# STM32F423 register map
File version: 1.2
CPU: CM4 r0p1, little endian, MPU, FPU, 4 interrupt priority bits
Registers are 32-bit, read-write, reset 0x0 unless marked. A register's access mark holds for its fields unless they carry their own. Offsets are from the block's base; [hi:lo] are bit positions; {n}, {i} and the like mark numbered series.

## RCC — Reset and clock control
Base 0x40023800
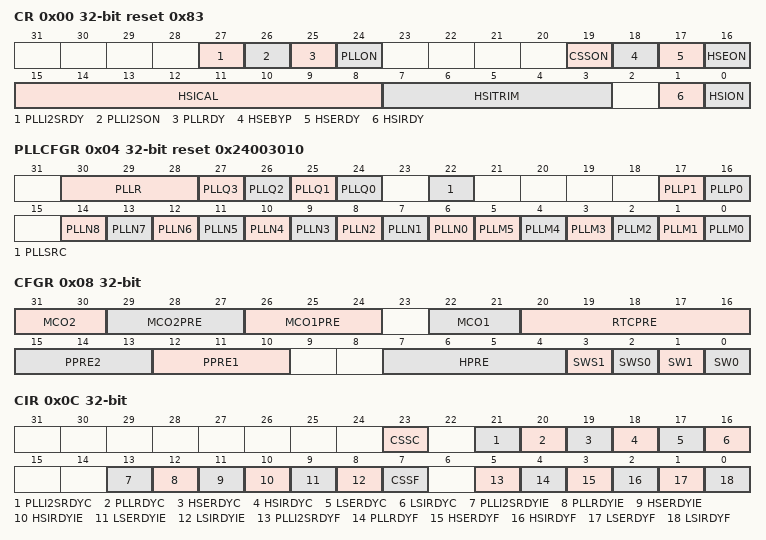
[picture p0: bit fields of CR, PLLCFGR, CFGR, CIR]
0x00 CR reset 0x83 — clock control register
  [27] PLLI2SRDY — PLLI2S clock ready flag
  [26] PLLI2SON — PLLI2S enable
  [25] PLLRDY — Main PLL (PLL) clock ready flag
  [24] PLLON — Main PLL (PLL) enable
  [19] CSSON — Clock security system enable
  [18] HSEBYP — HSE clock bypass
  [17] HSERDY — HSE clock ready flag
  [16] HSEON — HSE clock enable
  [15:8] HSICAL — Internal high-speed clock calibration
  [7:3] HSITRIM — Internal high-speed clock trimming
  [1] HSIRDY — Internal high-speed clock ready flag
  [0] HSION — Internal high-speed clock enable
0x04 PLLCFGR reset 0x24003010 — PLL configuration register
  [30:28] PLLR — Main PLL (PLL) division factor for I2S, DFSDM clocks
  [n+24] PLLQ{n} (n=0..3) — Main PLL (PLL) division factor for USB OTG FS, SDIO and random number generator clocks
  [22] PLLSRC — Main PLL(PLL) and audio PLL (PLLI2S) entry clock source
  [17] PLLP1 — Main PLL (PLL) division factor for main system clock
  [16] PLLP0 — Main PLL (PLL) division factor for main system clock
  [n+6] PLLN{n} (n=0..8) — Main PLL (PLL) multiplication factor for VCO
  [n] PLLM{n} (n=0..5) — Division factor for the main PLL (PLL) and audio PLL (PLLI2S) input clock
0x08 CFGR access per field — clock configuration register
  [31:30] MCO2 rw — Microcontroller clock output 2
  [29:27] MCO2PRE rw — MCO2 prescaler
  [26:24] MCO1PRE rw — MCO1 prescaler
  [22:21] MCO1 rw — Microcontroller clock output 1
  [20:16] RTCPRE rw — HSE division factor for RTC clock
  [15:13] PPRE2 rw — APB high-speed prescaler (APB2)
  [12:10] PPRE1 rw — APB Low speed prescaler (APB1)
  [7:4] HPRE rw — AHB prescaler
  [3] SWS1 ro — System clock switch status
  [2] SWS0 ro — System clock switch status
  [1] SW1 rw — System clock switch
  [0] SW0 rw — System clock switch
0x0C CIR access per field — clock interrupt register
  [23] CSSC wo — Clock security system interrupt clear
  [21] PLLI2SRDYC wo — PLLI2S ready interrupt clear
  [20] PLLRDYC wo — Main PLL(PLL) ready interrupt clear
  [19] HSERDYC wo — HSE ready interrupt clear
  [18] HSIRDYC wo — HSI ready interrupt clear
  [17] LSERDYC wo — LSE ready interrupt clear
  [16] LSIRDYC wo — LSI ready interrupt clear
  [13] PLLI2SRDYIE rw — PLLI2S ready interrupt enable
  [12] PLLRDYIE rw — Main PLL (PLL) ready interrupt enable
  [11] HSERDYIE rw — HSE ready interrupt enable
  [10] HSIRDYIE rw — HSI ready interrupt enable
  [9] LSERDYIE rw — LSE ready interrupt enable
  [8] LSIRDYIE rw — LSI ready interrupt enable
  [7] CSSF ro — Clock security system interrupt flag
  [5] PLLI2SRDYF ro — PLLI2S ready interrupt flag
  [4] PLLRDYF ro — Main PLL (PLL) ready interrupt flag
  [3] HSERDYF ro — HSE ready interrupt flag
  [2] HSIRDYF ro — HSI ready interrupt flag
  [1] LSERDYF ro — LSE ready interrupt flag
  [0] LSIRDYF ro — LSI ready interrupt flag
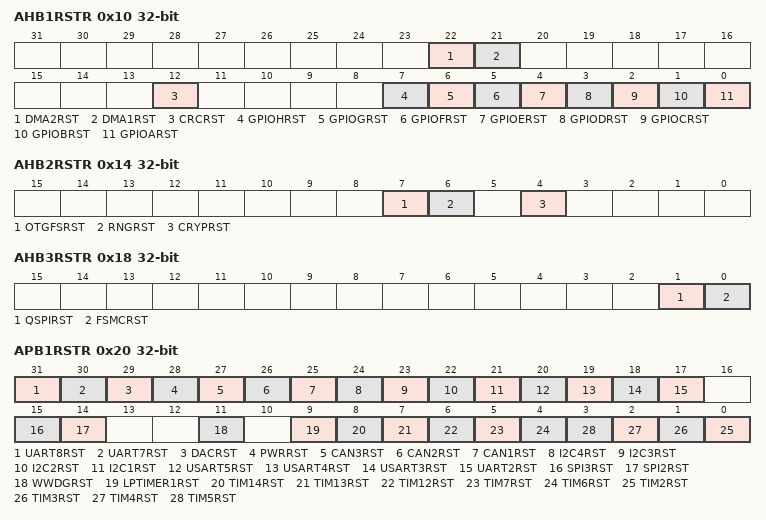
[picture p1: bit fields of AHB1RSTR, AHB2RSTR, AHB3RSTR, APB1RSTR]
0x10 AHB1RSTR — AHB1 peripheral reset register
  [22] DMA2RST — DMA2 reset
  [21] DMA1RST — DMA2 reset
  [12] CRCRST — CRC reset
  [7] GPIOHRST — IO port H reset
  [6] GPIOGRST — IO port G reset
  [5] GPIOFRST — IO port F reset
  [4] GPIOERST — IO port E reset
  [3] GPIODRST — IO port D reset
  [2] GPIOCRST — IO port C reset
  [1] GPIOBRST — IO port B reset
  [0] GPIOARST — IO port A reset
0x14 AHB2RSTR — AHB2 peripheral reset register
  [7] OTGFSRST — USB OTG FS module reset
  [6] RNGRST
  [4] CRYPRST — CRYP module reset
0x18 AHB3RSTR — peripheral reset register
  [1] QSPIRST — QUADSPI module reset
  [0] FSMCRST — Flexible memory controller module reset
0x20 APB1RSTR — APB1 peripheral reset register
  [31] UART8RST — UART 8 reset
  [30] UART7RST — UART 7 reset
  [29] DACRST — DAC reset
  [28] PWRRST — Power interface reset
  [27] CAN3RST — CAN 3 reset
  [26] CAN2RST
  [25] CAN1RST
  [24] I2C4RST
  [23] I2C3RST — I2C3 reset
  [22] I2C2RST — I2C 2 reset
  [21] I2C1RST — I2C 1 reset
  [20] USART5RST — USART5 reset
  [19] USART4RST — USART4 reset
  [18] USART3RST
  [17] UART2RST — USART 2 reset
  [15] SPI3RST — SPI 3 reset
  [14] SPI2RST — SPI 2 reset
  [11] WWDGRST — Window watchdog reset
  [9] LPTIMER1RST — LPTimer1 reset
  [8] TIM14RST
  [7] TIM13RST
  [6] TIM12RST
  [5] TIM7RST
  [4] TIM6RST
  [n-2] TIM{n}RST (n=2..5) — TIM{n} reset
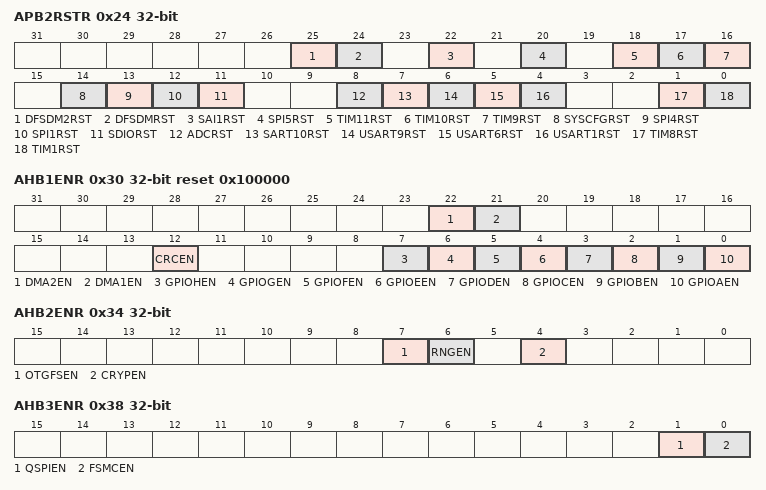
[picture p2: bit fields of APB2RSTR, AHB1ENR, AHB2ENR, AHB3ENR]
0x24 APB2RSTR — APB2 peripheral reset register
  [25] DFSDM2RST — DFSDM2 reset
  [24] DFSDMRST
  [22] SAI1RST — SAI1 reset
  [20] SPI5RST
  [18] TIM11RST — TIM11 reset
  [17] TIM10RST — TIM10 reset
  [16] TIM9RST — TIM9 reset
  [14] SYSCFGRST — System configuration controller reset
  [13] SPI4RST — SPI4 reset
  [12] SPI1RST — SPI 1 reset
  [11] SDIORST — SDIO reset
  [8] ADCRST — ADC interface reset (common to all ADCs)
  [7] SART10RST — USART10 reset
  [6] USART9RST — USART9 reset
  [5] USART6RST — USART6 reset
  [4] USART1RST — USART1 reset
  [1] TIM8RST
  [0] TIM1RST — TIM1 reset
0x30 AHB1ENR reset 0x100000 — AHB1 peripheral clock register
  [22] DMA2EN — DMA2 clock enable
  [21] DMA1EN — DMA1 clock enable
  [12] CRCEN — CRC clock enable
  [7] GPIOHEN — IO port H clock enable
  [6] GPIOGEN — IO port G clock enable
  [5] GPIOFEN — IO port F clock enable
  [4] GPIOEEN — IO port E clock enable
  [3] GPIODEN — IO port D clock enable
  [2] GPIOCEN — IO port C clock enable
  [1] GPIOBEN — IO port B clock enable
  [0] GPIOAEN — IO port A clock enable
0x34 AHB2ENR — AHB2 peripheral clock enable register
  [7] OTGFSEN — USB OTG FS clock enable
  [6] RNGEN
  [4] CRYPEN — CRYP clock enable
0x38 AHB3ENR — AHB3 peripheral clock enable register
  [1] QSPIEN — QUADSPI memory controller module clock enable
  [0] FSMCEN — Flexible memory controller module clock enable
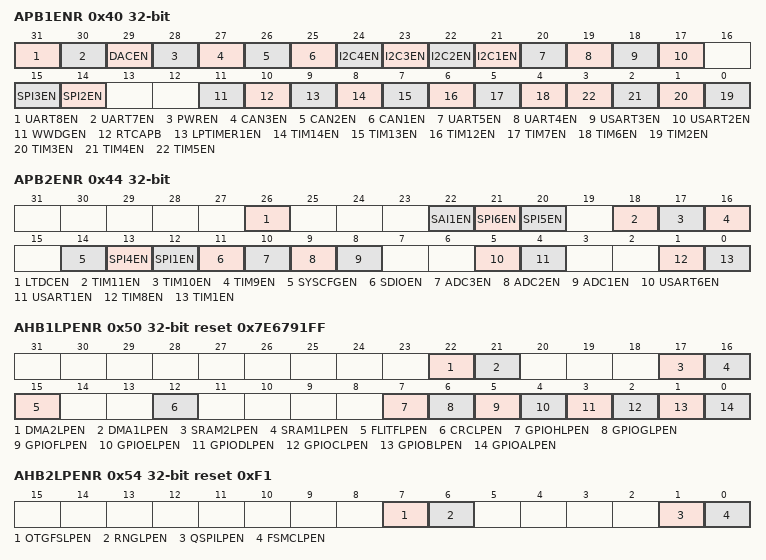
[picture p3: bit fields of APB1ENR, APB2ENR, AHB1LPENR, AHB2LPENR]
0x40 APB1ENR — APB1 peripheral clock enable register
  [31] UART8EN — UART8 clock enable
  [30] UART7EN — UART7 clock enable
  [29] DACEN — DAC clock enable
  [28] PWREN — Power interface clock enable
  [27] CAN3EN — CAN 3 clock enable
  [26] CAN2EN
  [25] CAN1EN
  [24] I2C4EN
  [23] I2C3EN — I2C3 clock enable
  [22] I2C2EN — I2C2 clock enable
  [21] I2C1EN — I2C1 clock enable
  [20] UART5EN — UART 5 clock enable
  [19] UART4EN — UART 4 clock enable
  [18] USART3EN
  [17] USART2EN — USART 2 clock enable
  [15] SPI3EN — SPI3 clock enable
  [14] SPI2EN — SPI2 clock enable
  [11] WWDGEN — Window watchdog clock enable
  [10] RTCAPB — clock enable
  [9] LPTIMER1EN — LPTimer 1 clock enable
  [8] TIM14EN
  [7] TIM13EN
  [6] TIM12EN
  [5] TIM7EN
  [4] TIM6EN
  [n-2] TIM{n}EN (n=2..5) — TIM{n} clock enable
0x44 APB2ENR — APB2 peripheral clock enable register
  [26] LTDCEN — LTDC clock enable
  [22] SAI1EN — SAI 1 clock enable
  [21] SPI6EN — SPI6 clock enable
  [20] SPI5EN — SPI5 clock enable
  [18] TIM11EN — TIM11 clock enable
  [17] TIM10EN — TIM10 clock enable
  [16] TIM9EN — TIM9 clock enable
  [14] SYSCFGEN — System configuration controller clock enable
  [13] SPI4EN — SPI4 clock enable
  [12] SPI1EN — SPI1 clock enable
  [11] SDIOEN — SDIO clock enable
  [10] ADC3EN — ADC3 clock enable
  [9] ADC2EN — ADC2 clock enable
  [8] ADC1EN — ADC1 clock enable
  [5] USART6EN — USART6 clock enable
  [4] USART1EN — USART1 clock enable
  [1] TIM8EN
  [0] TIM1EN — TIM1 clock enable
0x50 AHB1LPENR reset 0x7E6791FF — AHB1 peripheral clock enable in low power mode register
  [22] DMA2LPEN — DMA2 clock enable during Sleep mode
  [21] DMA1LPEN — DMA1 clock enable during Sleep mode
  [17] SRAM2LPEN — SRAM2interface clock enable during Sleep mode
  [16] SRAM1LPEN — SRAM 1interface clock enable during Sleep mode
  [15] FLITFLPEN — Flash interface clock enable during Sleep mode
  [12] CRCLPEN — CRC clock enable during Sleep mode
  [7] GPIOHLPEN — IO port H clock enable during Sleep mode
  [6] GPIOGLPEN — IO port G clock enable during sleep mode
  [5] GPIOFLPEN — IO port F clock enable during sleep mode
  [4] GPIOELPEN — IO port E clock enable during Sleep mode
  [3] GPIODLPEN — IO port D clock enable during Sleep mode
  [2] GPIOCLPEN — IO port C clock enable during Sleep mode
  [1] GPIOBLPEN — IO port B clock enable during Sleep mode
  [0] GPIOALPEN — IO port A clock enable during sleep mode
0x54 AHB2LPENR reset 0xF1 — AHB2 peripheral clock enable in low power mode register
  [7] OTGFSLPEN — USB OTG FS clock enable during Sleep mode
  [6] RNGLPEN
  [1] QSPILPEN — QUADSPI memory controller module clock enable during Sleep mode
  [0] FSMCLPEN — Flexible memory controller module clock enable during Sleep mode
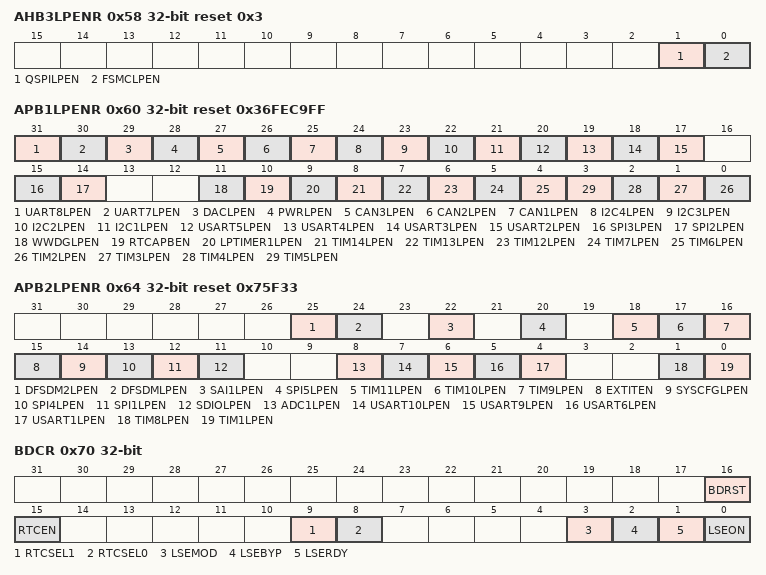
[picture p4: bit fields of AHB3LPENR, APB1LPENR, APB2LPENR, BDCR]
0x58 AHB3LPENR reset 0x3 — AHB3 peripheral clock enable in low power mode register
  [1] QSPILPEN — QUADSPI memory controller module clock enable during Sleep mode
  [0] FSMCLPEN — Flexible memory controller module clock enable during Sleep mode
0x60 APB1LPENR reset 0x36FEC9FF — APB1 peripheral clock enable in low power mode register
  [31] UART8LPEN — UART8 clock enable during Sleep mode
  [30] UART7LPEN — UART7 clock enable during Sleep mode
  [29] DACLPEN — DAC clock enable during Sleep mode
  [28] PWRLPEN — Power interface clock enable during Sleep mode
  [27] CAN3LPEN — CAN3 clock enable during Sleep mode
  [26] CAN2LPEN
  [25] CAN1LPEN
  [24] I2C4LPEN
  [23] I2C3LPEN — I2C3 clock enable during Sleep mode
  [22] I2C2LPEN — I2C2 clock enable during Sleep mode
  [21] I2C1LPEN — I2C1 clock enable during Sleep mode
  [20] USART5LPEN — USART5 clock enable during Sleep mode
  [19] USART4LPEN — USART4 clock enable during Sleep mode
  [18] USART3LPEN
  [17] USART2LPEN — USART2 clock enable during Sleep mode
  [15] SPI3LPEN — SPI3 clock enable during Sleep mode
  [14] SPI2LPEN — SPI2 clock enable during Sleep mode
  [11] WWDGLPEN — Window watchdog clock enable during Sleep mode
  [10] RTCAPBEN — RTC APB clock enable during Sleep mode
  [9] LPTIMER1LPEN — TIM14 clock enable during Sleep mode
  [8] TIM14LPEN
  [7] TIM13LPEN
  [6] TIM12LPEN
  [5] TIM7LPEN
  [4] TIM6LPEN
  [n-2] TIM{n}LPEN (n=2..5) — TIM{n} clock enable during Sleep mode
0x64 APB2LPENR reset 0x75F33 — APB2 peripheral clock enabled in low power mode register
  [25] DFSDM2LPEN — DFSDM2 clock enable during Sleep mode
  [24] DFSDMLPEN
  [22] SAI1LPEN — SAI1 clock enable during Sleep mode
  [20] SPI5LPEN — SPI5 clock enable during Sleep mode
  [18] TIM11LPEN — TIM11 clock enable during Sleep mode
  [17] TIM10LPEN — TIM10 clock enable during Sleep mode
  [16] TIM9LPEN — TIM9 clock enable during sleep mode
  [15] EXTITEN — EXTIT APB and SYSCTRL PFREE clock enable during Sleep mode
  [14] SYSCFGLPEN — System configuration controller clock enable during Sleep mode
  [13] SPI4LPEN — SPI4 clock enable during Sleep mode
  [12] SPI1LPEN — SPI 1 clock enable during Sleep mode
  [11] SDIOLPEN — SDIO clock enable during Sleep mode
  [8] ADC1LPEN — ADC1 clock enable during Sleep mode
  [7] USART10LPEN — USART10 clock enable during Sleep mode
  [6] USART9LPEN — USART9 clock enable during Sleep mode
  [5] USART6LPEN — USART6 clock enable during Sleep mode
  [4] USART1LPEN — USART1 clock enable during Sleep mode
  [1] TIM8LPEN
  [0] TIM1LPEN — TIM1 clock enable during Sleep mode
0x70 BDCR access per field — Backup domain control register
  [16] BDRST rw — Backup domain software reset
  [15] RTCEN rw — RTC clock enable
  [9] RTCSEL1 rw — RTC clock source selection
  [8] RTCSEL0 rw — RTC clock source selection
  [3] LSEMOD rw — External low-speed oscillator bypass
  [2] LSEBYP rw — External low-speed oscillator bypass
  [1] LSERDY ro — External low-speed oscillator ready
  [0] LSEON rw — External low-speed oscillator enable
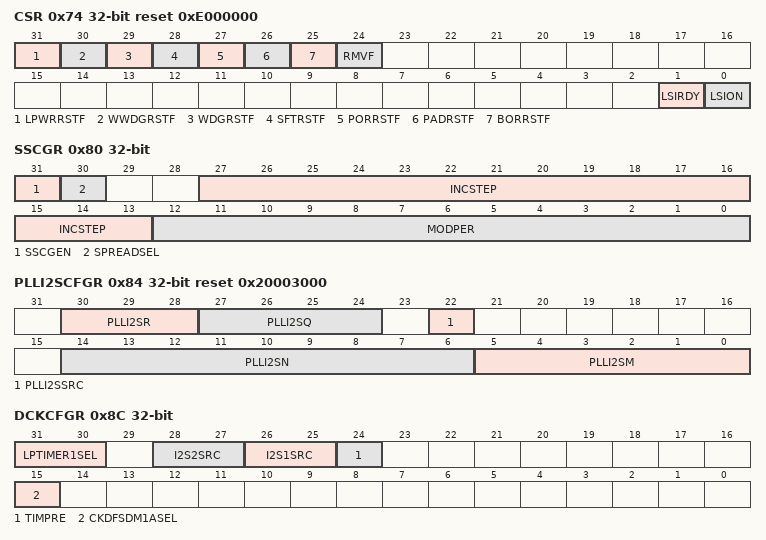
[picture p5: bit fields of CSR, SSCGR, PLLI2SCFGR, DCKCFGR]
0x74 CSR access per field reset 0xE000000 — clock control & status register
  [31] LPWRRSTF rw — Low-power reset flag
  [30] WWDGRSTF rw — Window watchdog reset flag
  [29] WDGRSTF rw — Independent watchdog reset flag
  [28] SFTRSTF rw — Software reset flag
  [27] PORRSTF rw — POR/PDR reset flag
  [26] PADRSTF rw — PIN reset flag
  [25] BORRSTF rw — BOR reset flag
  [24] RMVF rw — Remove reset flag
  [1] LSIRDY ro — Internal low-speed oscillator ready
  [0] LSION rw — Internal low-speed oscillator enable
0x80 SSCGR — spread spectrum clock generation register
  [31] SSCGEN — Spread spectrum modulation enable
  [30] SPREADSEL — Spread Select
  [27:13] INCSTEP — Incrementation step
  [12:0] MODPER — Modulation period
0x84 PLLI2SCFGR reset 0x20003000 — PLLI2S configuration register
  [30:28] PLLI2SR — PLLI2S division factor for I2S clocks
  [27:24] PLLI2SQ — PLLI2S division factor for USB OTG FS/SDIO/RNG clock
  [22] PLLI2SSRC — PLLI2S entry clock source
  [14:6] PLLI2SN — PLLI2S multiplication factor for VCO
  [5:0] PLLI2SM — Division factor for the main PLL (PLL) and audio PLL (PLLI2S) input clock
0x8C DCKCFGR — Dedicated Clocks Configuration Register
  [31:30] LPTIMER1SEL — LPTIMER1 kernel clock selection.
  [28:27] I2S2SRC — I2S APB2 clocks source selection (I2S1/4/5)
  [26:25] I2S1SRC — I2S APB1 clocks source selection (I2S2/3)
  [24] TIMPRE — Timers clocks prescalers selection
  [15] CKDFSDM1ASEL — DFSDM1 audio clock selection.
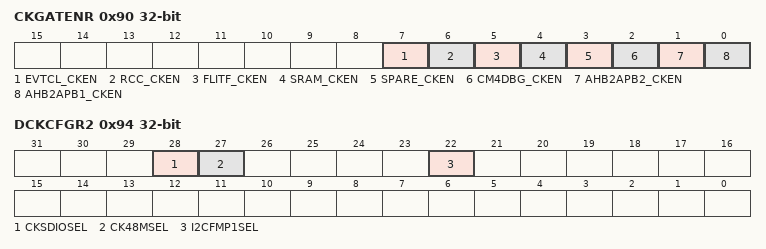
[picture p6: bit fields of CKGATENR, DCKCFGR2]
0x90 CKGATENR — RCC clocks gated enable register
  [7] EVTCL_CKEN
  [6] RCC_CKEN — RCC clock enable
  [5] FLITF_CKEN — Flash Interface clock enable
  [4] SRAM_CKEN — SRQAM controller clock enable
  [3] SPARE_CKEN — Spare clock enable
  [2] CM4DBG_CKEN — Cortex M4 ETM clock enable
  [1] AHB2APB2_CKEN — AHB to APB2 Bridge clock enable
  [0] AHB2APB1_CKEN — AHB to APB1 Bridge clock enable
0x94 DCKCFGR2 — Dedicated Clocks Configuration Register
  [28] CKSDIOSEL — SDIO clock selection.
  [27] CK48MSEL — SDIO/USBFS clock selection.
  [22] I2CFMP1SEL — I2CFMP1 kernel clock source selection

## Notices in the file
Copyright (c) 2024 STMicroelectronics.
SPDX-License-Identifier: Apache-2.0
Licensed under the Apache License, Version 2.0 (the "License");
you may not use this file except in compliance with the License.
You may obtain a copy of the License at
http://www.apache.org/licenses/LICENSE-2.0
Unless required by applicable law or agreed to in writing, software
distributed under the License is distributed on an "AS IS" BASIS,
WITHOUT WARRANTIES OR CONDITIONS OF ANY KIND, either express or implied.
See the License for the specific language governing permissions and
limitations under the License.
